# STM32WLE4C8U6 register map
File version: 1.0
Registers are 32-bit, access not given, reset 0x0 unless marked. A register's access mark holds for its fields unless they carry their own. Offsets are from the block's base; [hi:lo] are bit positions; {n}, {i} and the like mark numbered series.

## PWR
Base 0x58000400
0x00 CR1
  [14] LPR, [10:9] VOS, [8] DBP, [31:6] s, [5] FPDS, [4] FPDR, [3] SUBGHZSPINSSSEL, [2:0] LPMS
0x04 CR2
  [6] PVME3, [31:4] s, [3:1] PLS, [0] PVDE
0x08 CR3
  [15] EIWUL, [13] EWRFIRQ, [11] EWRFBUSY, [10] APC, [9] RRS, [8] EWPVD, [7] ULPEN, [31:3] s, [2] EWUP3, [1] EWUP2, [0] EWUP1
0x0C CR4
  [11] WRFBUSYP, [9] VBRS, [8] VBE, [31:3] s, [2] WP3, [1] WP2, [0] WP1
0x10 SR1
  [15] WUFI, [11] WRFBUSYF, [8] WPVDF, [31:3] s, [2] WUF3, [1] WUF2, [0] WUF1
0x14 SR2
  [14] PVMO3, [11] PVDO, [10] VOSF, [9] REGLPF, [8] REGLPS, [7] FLASHRDY, [6] REGMRS, [5] RFEOLF, [4] LDORDY, [3] SMPSRDY, [2] RFBUSYMS, [1] RFBUSYS, [31:0] s
0x18 SCR
  [11] CWRFBUSYF, [8] CWPVDF, [31:3] s, [2] CWUF3, [1] CWUF2, [0] CWUF1
0x1C CR5
  [15] SMPSEN, [14] RFEOLEN, [31:0] s
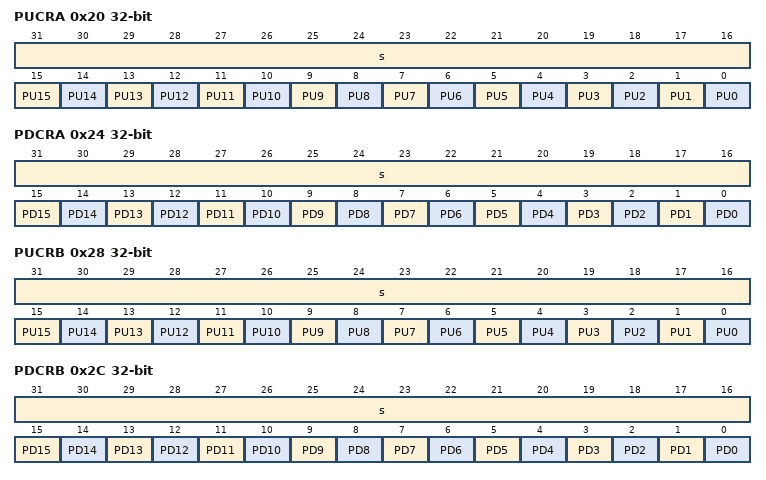
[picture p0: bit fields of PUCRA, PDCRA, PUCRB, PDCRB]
0x20 PUCRA
  [31:16] s, [n] PU{n} (n=0..15)
0x24 PDCRA
  [31:16] s, [n] PD{n} (n=0..15)
0x28 PUCRB
  [31:16] s, [n] PU{n} (n=0..15)
0x2C PDCRB
  [31:16] s, [n] PD{n} (n=0..15)
0x30 PUCRC
  [15] PU15, [14] PU14, [13] PU13, [31:7] s, [n] PU{n} (n=0..6)
0x34 PDCRC
  [15] PD15, [14] PD14, [13] PD13, [31:7] s, [n] PD{n} (n=0..6)
0x58 PUCRH
  [3] PU3, [31:0] s
0x5C PDCRH
  [3] PD3, [31:0] s
0x88 EXTSCR
  [14] C1DS, [10] C1STOPF, [9] C1STOP2F, [8] C1SBF, [31:1] s, [0] C1CSSF
0x90 SUBGHZSPICR
  [15] NSS, [31:0] s

## EXTI
Base 0x58000800
0x00 RTSR1
  [22] RT22, [21] RT21, [31:17] s, [n] RT{n} (n=0..16)
0x04 FTSR1
  [22] FT22, [21] FT21, [31:17] s, [n] FT{n} (n=0..16)
0x08 SWIER1
  [22] SWI22, [21] SWI21, [31:17] s, [n] SWI{n} (n=0..16)
0x0C PR1
  [22] PIF22, [21] PIF21, [31:17] s, [n] PIF{n} (n=0..16)
0x20 RTSR2
  [13] RT45, [2] RT34, [31:0] s
0x24 FTSR2
  [13] FT45, [2] FT34, [31:0] s
0x28 SWIER2
  [13] SWI45, [2] SWI34, [31:0] s
0x2C PR2
  [13] PIF45, [2] PIF34, [31:0] s
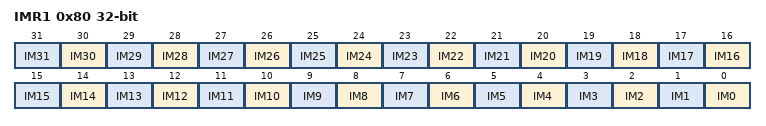
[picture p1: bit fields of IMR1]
0x80 IMR1
  [n] IM{n} (n=0..31)
0x84 EMR1
  [n] EM{n} (n=17..22), [31:16] s, [n] EM{n} (n=0..15)
0x90 IMR2
  [13] IM45, [12] IM44, [14:11] IM46, [10] IM42, [6] IM38, [2] IM34, [31:0] s

## TRNG
Base 0x58001000
0x00 CR
  [31] CONFIGLOCK, [30] CONDRST, [25:20] RNG_CONFIG1, [19:16] CLKDIV, [15:13] RNG_CONFIG2, [12] NISTC, [11:8] RNG_CONFIG3, [5] CED, [3] IE, [2] RNGEN, [29:0] s
0x04 SR
  [6] SEIS, [5] CEIS, [31:3] s, [2] SECS, [1] CECS, [0] DRDY
0x08 DR
  [31:0] RNDATA
0x10 HTCR
  [31:0] HTCFG

## HSEM
Base 0x58001400
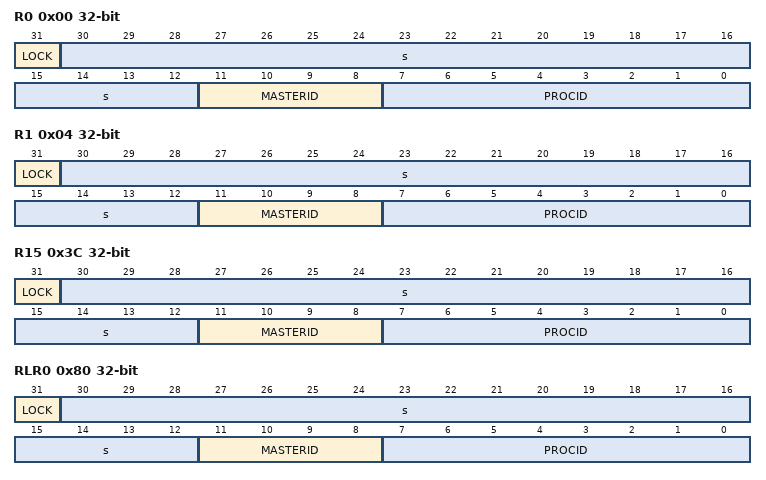
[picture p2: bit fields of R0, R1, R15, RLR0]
0x00 R0
  [31] LOCK, [30:12] s, [11:8] MASTERID, [7:0] PROCID
0x04 R1
  [31] LOCK, [30:12] s, [11:8] MASTERID, [7:0] PROCID
0x3C R15
  [31] LOCK, [30:12] s, [11:8] MASTERID, [7:0] PROCID
0x80 RLR0
  [31] LOCK, [30:12] s, [11:8] MASTERID, [7:0] PROCID
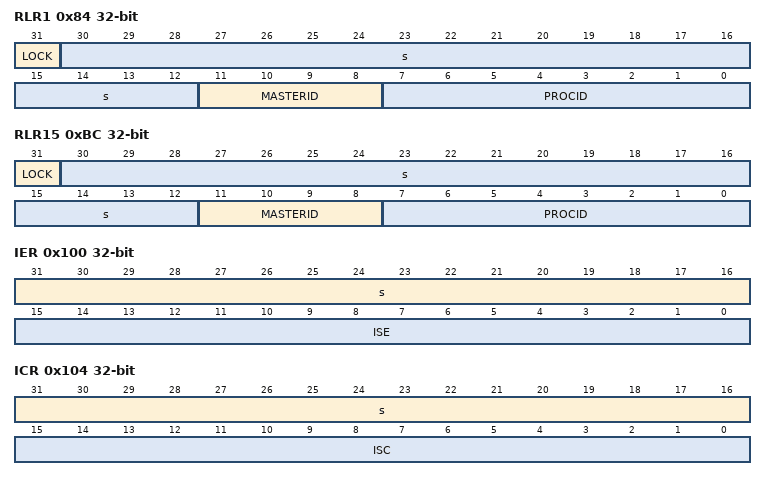
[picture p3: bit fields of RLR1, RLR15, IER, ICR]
0x84 RLR1
  [31] LOCK, [30:12] s, [11:8] MASTERID, [7:0] PROCID
0xBC RLR15
  [31] LOCK, [30:12] s, [11:8] MASTERID, [7:0] PROCID
0x100 IER
  [31:16] s, [15:0] ISE
0x104 ICR
  [31:16] s, [15:0] ISC
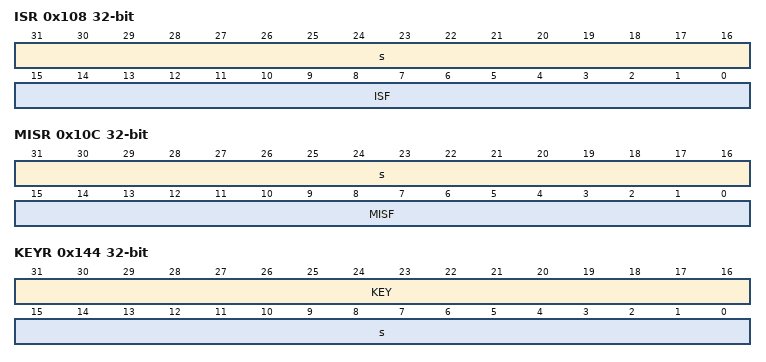
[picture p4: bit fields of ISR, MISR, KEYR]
0x108 ISR
  [31:16] s, [15:0] ISF
0x10C MISR
  [31:16] s, [15:0] MISF
0x140 CR
  [31:16] KEY, [11:8] MASTERID, [15:0] s
0x144 KEYR
  [31:16] KEY, [15:0] s

## AES
Base 0x58001800
0x00 CR
  [23:20] NPBLB, [18] KEYSIZE, [31:15] s, [14:13] GCMPH, [12] DMAOUTEN, [11] DMAINEN, [10] ERRIE, [9] CCFIE, [8] ERRC, [7] CCFC, [16:5] CHMOD, [4:3] MODE, [2:1] DATATYPE, [0] EN
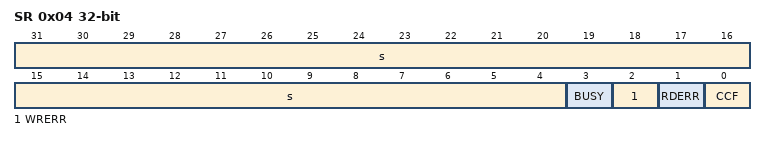
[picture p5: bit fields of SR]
0x04 SR
  [31:4] s, [3] BUSY, [2] WRERR, [1] RDERR, [0] CCF
0x08 DINR
  [31:0] DIN
0x0C DOUTR
  [31:0] DOUT
{0x10+4i} KEYR{i} (i=0..3)
  [31:0] KEY
{0x20+4i} IVR{i} (i=0..3)
  [31:0] IVI
{0x20+4i} KEYR{i} (i=4..7)
  [31:0] KEY
{0x40+4i} SUSP{i}R (i=0..7)
  [31:0] SUSP

## PKA
Base 0x58002000
Same registers: PKARAM 0x58002400, PKARAM 0x58002400, PKA 0x58003400, PKA 0x58003400
0x00 CR
  [20] ADDRERRIE, [19] RAMERRIE, [17] PROCENDIE, [13:8] MODE, [31:2] s, [1] START, [0] EN
0x04 SR
  [20] ADDRERRF, [19] RAMERRF, [17] PROCENDF, [16] BUSY, [31:0] s
0x08 CLRFR
  [20] ADDRERRFC, [19] RAMERRFC, [17] PROCENDFC, [31:0] s

## SUBGHZSPI
Base 0x58010000
0x6AC GBSYNCR
  [6] SBITSYNCEN, [5] RXDINV, [4] BITSYNCDIS, [7:0] s
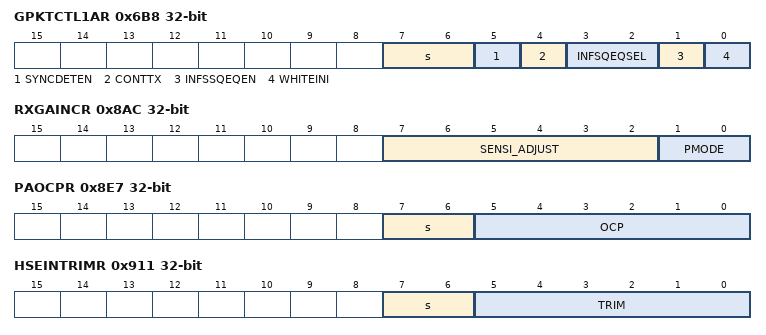
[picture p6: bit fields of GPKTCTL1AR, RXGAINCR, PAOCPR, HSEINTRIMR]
0x6B8 GPKTCTL1AR
  [7:6] s, [5] SYNCDETEN, [4] CONTTX, [3:2] INFSQEQSEL, [1] INFSSQEQEN, [0] WHITEINI
0x6B9 GWHITEINIRL
  [7:0] WHITEINI
0x6BC GCRCINIRH
  [7:0] CRCINI
0x6BD GCRCINIRL
  [7:0] CRCINI
0x6BE GCRCPOLRH
  [7:0] CRCPOL
0x6BF GCRCPOLRL
  [7:0] CRCPOL
0x6C0 GSYNCR7
  [7:0] SYNCWORD
0x6C1 GSYNCR6
  [7:0] SYNCWORD
0x6C2 GSYNCR5
  [7:0] SYNCWORD
0x6C3 GSYNCR4
  [7:0] SYNCWORD
0x6C4 GSYNCR3
  [7:0] SYNCWORD
0x6C5 GSYNCR2
  [7:0] SYNCWORD
0x6C6 GSYNCR1
  [7:0] SYNCWORD
0x6C7 GSYNCR0
  [7:0] SYNCWORD
0x740 LSYNCRH
  [7:0] SYNCWORD
0x741 LSYNCRL
  [7:0] SYNCWORD
0x819 RNGR3
  [7:0] RNDATA
0x81A RNGR2
  [7:0] RNDATA
0x81B RNGR1
  [7:0] RNDATA
0x81C RNGR0
  [7:0] RNDATA
0x8AC RXGAINCR
  [7:2] SENSI_ADJUST, [1:0] PMODE
0x8E7 PAOCPR
  [7:6] s, [5:0] OCP
0x911 HSEINTRIMR
  [7:6] s, [5:0] TRIM
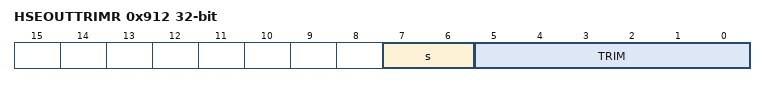
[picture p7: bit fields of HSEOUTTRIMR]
0x912 HSEOUTTRIMR
  [7:6] s, [5:0] TRIM
0x916 SMPSC0R
  [6] CLKDE, [7:0] s
0x91A PCR
  [6] CLE, [5:4] CLV, [7:0] s
0x923 SMPSC2R
  [2:1] DRV, [7:0] s
